AUTOSAR XML (schema 4-0-3)
package /Components
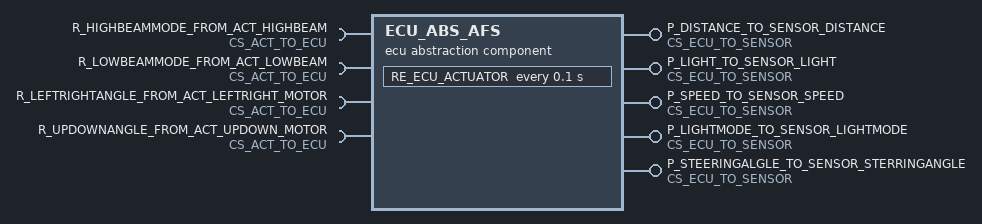
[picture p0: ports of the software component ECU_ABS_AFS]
  ecu abstraction sw component type ECU_ABS_AFS
    4 x require port, all with required-interface=CS_ACT_TO_ECU:
      R_HIGHBEAMMODE_FROM_ACT_HIGHBEAM
      R_LOWBEAMMODE_FROM_ACT_LOWBEAM
      R_LEFTRIGHTANGLE_FROM_ACT_LEFTRIGHT_MOTOR
      R_UPDOWNANGLE_FROM_ACT_UPDOWN_MOTOR
    5 x provide port, all with server-com-spec{operation=OPER_ECU_TO_SENSOR, queue-length=10}, provided-interface=CS_ECU_TO_SENSOR:
      P_DISTANCE_TO_SENSOR_DISTANCE
      P_LIGHT_TO_SENSOR_LIGHT
      P_SPEED_TO_SENSOR_SPEED
      P_LIGHTMODE_TO_SENSOR_LIGHTMODE
      P_STEERINGALGLE_TO_SENSOR_STERRINGANGLE
    behavior IB_ECU_ABS
      timing event TE_ACTUATOR: start-on-event=RE_ECU_ACTUATOR, period=0.1
      5 x operation invoked event:
        OIE_LIGHT: start-on-event=RE_ECU_LIGHT, operation=P_LIGHT_TO_SENSOR_LIGHT.OPER_ECU_TO_SENSOR
        OIE_SPEED: start-on-event=RE_ECU_SPEED, operation=P_SPEED_TO_SENSOR_SPEED.OPER_ECU_TO_SENSOR
        OIE_STEERINGANGLE: start-on-event=RE_ECU_STEERINGANGLE, operation=P_STEERINGALGLE_TO_SENSOR_STERRINGANGLE.OPER_ECU_TO_SENSOR
        OIE_DISTANCE: start-on-event=RE_ECU_DISTANCE, operation=P_DISTANCE_TO_SENSOR_DISTANCE.OPER_ECU_TO_SENSOR
        OIE_LIGHTMODE: start-on-event=RE_ECU_LIGHTMODE, operation=P_LIGHTMODE_TO_SENSOR_LIGHTMODE.OPER_ECU_TO_SENSOR
      6 x runnable:
        RE_ECU_ACTUATOR
          4 x sync call:
            SynchronousServerCallPoint_0: operation=R_UPDOWNANGLE_FROM_ACT_UPDOWN_MOTOR.OPER_ACT_TO_ECU
            SynchronousServerCallPoint_1: operation=R_HIGHBEAMMODE_FROM_ACT_HIGHBEAM.OPER_ACT_TO_ECU
            SynchronousServerCallPoint_2: operation=R_LEFTRIGHTANGLE_FROM_ACT_LEFTRIGHT_MOTOR.OPER_ACT_TO_ECU
            SynchronousServerCallPoint_3: operation=R_LOWBEAMMODE_FROM_ACT_LOWBEAM.OPER_ACT_TO_ECU
        RE_ECU_DISTANCE
        RE_ECU_LIGHT
        RE_ECU_LIGHTMODE
        RE_ECU_SPEED
        RE_ECU_STEERINGANGLE
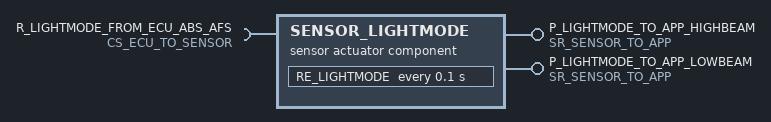
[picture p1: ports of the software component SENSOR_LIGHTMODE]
  sensor actuator sw component type SENSOR_LIGHTMODE
    provide port P_LIGHTMODE_TO_APP_HIGHBEAM: provided-interface=SR_SENSOR_TO_APP
    provide port P_LIGHTMODE_TO_APP_LOWBEAM: provided-interface=SR_SENSOR_TO_APP
    require port R_LIGHTMODE_FROM_ECU_ABS_AFS: required-interface=CS_ECU_TO_SENSOR
    behavior IB_SENSOR_LIGHTMODE
      timing event TE_LIGHTMODE: start-on-event=RE_LIGHTMODE, period=0.1
      runnable RE_LIGHTMODE
        asynchronous server call result point AsynchronousServerCallResultPoint_0: asynchronous-server-call-point=RE_LIGHTMODE/AsynchronousServerCallPoint_0
        data-send-points:
          access DSP_VDP_SENSOR_TO_APP_0: accessed-variable=P_LIGHTMODE_TO_APP_HIGHBEAM.VDP_SENSOR_TO_APP
          access DSP_VDP_SENSOR_TO_APP_1: accessed-variable=P_LIGHTMODE_TO_APP_LOWBEAM.VDP_SENSOR_TO_APP
        async call AsynchronousServerCallPoint_0: operation=R_LIGHTMODE_FROM_ECU_ABS_AFS.OPER_ECU_TO_SENSOR
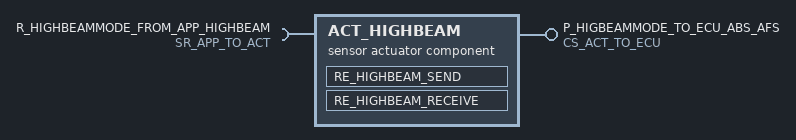
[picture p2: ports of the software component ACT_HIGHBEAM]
  sensor actuator sw component type ACT_HIGHBEAM
    require port R_HIGHBEAMMODE_FROM_APP_HIGHBEAM: required-interface=SR_APP_TO_ACT
    provide port P_HIGBEAMMODE_TO_ECU_ABS_AFS: server-com-spec{operation=OPER_ACT_TO_ECU, queue-length=10}, provided-interface=CS_ACT_TO_ECU
    behavior IB_ACT_HIGHBEAM
      operation invoked event OIE_HIGHBEAM_SEND: start-on-event=RE_HIGHBEAM_SEND, operation=P_HIGBEAMMODE_TO_ECU_ABS_AFS.OPER_ACT_TO_ECU
      data received event DRE_HIGHBEAM_RECEIVE: start-on-event=RE_HIGHBEAM_RECEIVE, data=R_HIGHBEAMMODE_FROM_APP_HIGHBEAM.VDP_APP_TO_ACT
      explicit-inter-runnable-variables:
        data Explicit_VariableDataPrototype_0: type=sint32
      runnable RE_HIGHBEAM_SEND
        read-local-variables:
          access ReadLocalVariables_VariableAccess_0: accessed-variable=IB_ACT_HIGHBEAM/Explicit_VariableDataPrototype_0
      runnable RE_HIGHBEAM_RECEIVE
        data-receive-point-by-values:
          access DRPV_VDP_APP_TO_ACT_0: accessed-variable=R_HIGHBEAMMODE_FROM_APP_HIGHBEAM.VDP_APP_TO_ACT
        written-local-variables:
          access WrittenLocalVariables_VariableAccess_0: accessed-variable=IB_ACT_HIGHBEAM/Explicit_VariableDataPrototype_0
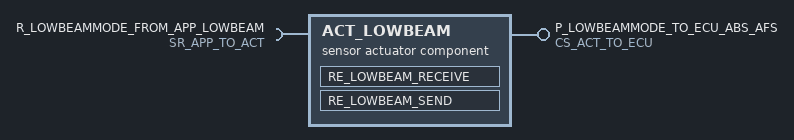
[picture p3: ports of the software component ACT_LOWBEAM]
  sensor actuator sw component type ACT_LOWBEAM
    require port R_LOWBEAMMODE_FROM_APP_LOWBEAM: required-interface=SR_APP_TO_ACT
    provide port P_LOWBEAMMODE_TO_ECU_ABS_AFS: server-com-spec{operation=OPER_ACT_TO_ECU, queue-length=10}, provided-interface=CS_ACT_TO_ECU
    behavior IB_ACT_LOWBEAM
      data received event DRE_LOWBEAM_RECEIVE: start-on-event=RE_LOWBEAM_RECEIVE, data=R_LOWBEAMMODE_FROM_APP_LOWBEAM.VDP_APP_TO_ACT
      operation invoked event OIE_LOWBEAM_SEND: start-on-event=RE_LOWBEAM_SEND, operation=P_LOWBEAMMODE_TO_ECU_ABS_AFS.OPER_ACT_TO_ECU
      explicit-inter-runnable-variables:
        data Explicit_VariableDataPrototype_0: type=sint32
      runnable RE_LOWBEAM_RECEIVE
        data-receive-point-by-values:
          access DRPV_VDP_APP_TO_ACT_0: accessed-variable=R_LOWBEAMMODE_FROM_APP_LOWBEAM.VDP_APP_TO_ACT
        written-local-variables:
          access WrittenLocalVariables_VariableAccess_0: accessed-variable=IB_ACT_LOWBEAM/Explicit_VariableDataPrototype_0
      runnable RE_LOWBEAM_SEND
        read-local-variables:
          access ReadLocalVariables_VariableAccess_0: accessed-variable=IB_ACT_LOWBEAM/Explicit_VariableDataPrototype_0
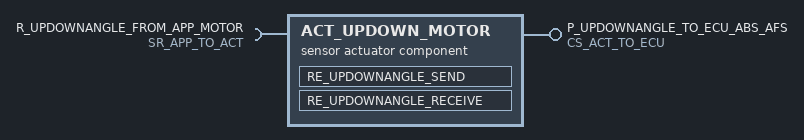
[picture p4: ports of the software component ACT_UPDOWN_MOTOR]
  sensor actuator sw component type ACT_UPDOWN_MOTOR
    require port R_UPDOWNANGLE_FROM_APP_MOTOR: required-interface=SR_APP_TO_ACT
    provide port P_UPDOWNANGLE_TO_ECU_ABS_AFS: server-com-spec{operation=OPER_ACT_TO_ECU, queue-length=10}, provided-interface=CS_ACT_TO_ECU
    behavior IB_ACT_UPDOWN_MOTOR
      operation invoked event OIE_UPDOWNANGLE_SEND: start-on-event=RE_UPDOWNANGLE_SEND, operation=P_UPDOWNANGLE_TO_ECU_ABS_AFS.OPER_ACT_TO_ECU
      data received event DRE_UPDOWNANGLE_RECEIVE: start-on-event=RE_UPDOWNANGLE_RECEIVE, data=R_UPDOWNANGLE_FROM_APP_MOTOR.VDP_APP_TO_ACT
      explicit-inter-runnable-variables:
        data Explicit_VariableDataPrototype_0: type=sint32
      runnable RE_UPDOWNANGLE_SEND
        read-local-variables:
          access ReadLocalVariables_VariableAccess_0: accessed-variable=IB_ACT_UPDOWN_MOTOR/Explicit_VariableDataPrototype_0
      runnable RE_UPDOWNANGLE_RECEIVE
        data-receive-point-by-values:
          access DRPV_VDP_APP_TO_ACT_0: accessed-variable=R_UPDOWNANGLE_FROM_APP_MOTOR.VDP_APP_TO_ACT
        written-local-variables:
          access WrittenLocalVariables_VariableAccess_0: accessed-variable=IB_ACT_UPDOWN_MOTOR/Explicit_VariableDataPrototype_0
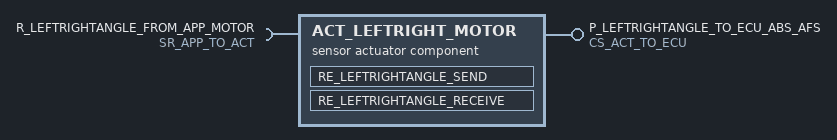
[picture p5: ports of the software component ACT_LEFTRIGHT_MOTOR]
  sensor actuator sw component type ACT_LEFTRIGHT_MOTOR
    require port R_LEFTRIGHTANGLE_FROM_APP_MOTOR: required-interface=SR_APP_TO_ACT
    provide port P_LEFTRIGHTANGLE_TO_ECU_ABS_AFS: server-com-spec{operation=OPER_ACT_TO_ECU, queue-length=10}, provided-interface=CS_ACT_TO_ECU
    behavior IB_ACT_LEFTRIGHT_MOTOR
      data received event DRE_LEFTRIGHTANGLE_RECEIVE: start-on-event=RE_LEFTRIGHTANGLE_RECEIVE, data=R_LEFTRIGHTANGLE_FROM_APP_MOTOR.VDP_APP_TO_ACT
      operation invoked event OIE_LEFTRIGHTANGLE_SEND: start-on-event=RE_LEFTRIGHTANGLE_SEND, operation=P_LEFTRIGHTANGLE_TO_ECU_ABS_AFS.OPER_ACT_TO_ECU
      explicit-inter-runnable-variables:
        data Explicit_VariableDataPrototype_0: type=sint32
      runnable RE_LEFTRIGHTANGLE_SEND
        read-local-variables:
          access ReadLocalVariables_VariableAccess_0: accessed-variable=IB_ACT_LEFTRIGHT_MOTOR/Explicit_VariableDataPrototype_0
      runnable RE_LEFTRIGHTANGLE_RECEIVE
        data-receive-point-by-values:
          access DRPV_VDP_APP_TO_ACT_0: accessed-variable=R_LEFTRIGHTANGLE_FROM_APP_MOTOR.VDP_APP_TO_ACT
        written-local-variables:
          access WrittenLocalVariables_VariableAccess_0: accessed-variable=IB_ACT_LEFTRIGHT_MOTOR/Explicit_VariableDataPrototype_0
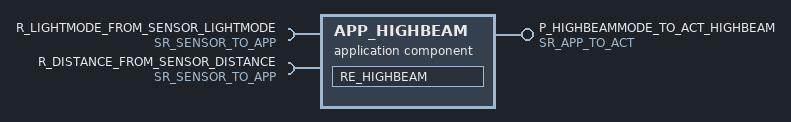
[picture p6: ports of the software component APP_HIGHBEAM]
  application sw component type APP_HIGHBEAM
    require port R_LIGHTMODE_FROM_SENSOR_LIGHTMODE: required-interface=SR_SENSOR_TO_APP
    require port R_DISTANCE_FROM_SENSOR_DISTANCE: required-interface=SR_SENSOR_TO_APP
    provide port P_HIGHBEAMMODE_TO_ACT_HIGHBEAM: provided-interface=SR_APP_TO_ACT
    behavior IB_APP_HIGHBEAM
      data received event DRE_LIGHTMODE: start-on-event=RE_HIGHBEAM, data=R_LIGHTMODE_FROM_SENSOR_LIGHTMODE.VDP_SENSOR_TO_APP
      data received event DRE_DISTANCE: start-on-event=RE_HIGHBEAM, data=R_DISTANCE_FROM_SENSOR_DISTANCE.VDP_SENSOR_TO_APP
      runnable RE_HIGHBEAM
        data-receive-point-by-arguments:
          access DRPA_VDP_SENSOR_TO_APP_0: accessed-variable=R_LIGHTMODE_FROM_SENSOR_LIGHTMODE.VDP_SENSOR_TO_APP
          access DRPA_VDP_SENSOR_TO_APP_1: accessed-variable=R_DISTANCE_FROM_SENSOR_DISTANCE.VDP_SENSOR_TO_APP
        data-send-points:
          access DSP_VDP_APP_TO_ACT_0: accessed-variable=P_HIGHBEAMMODE_TO_ACT_HIGHBEAM.VDP_APP_TO_ACT
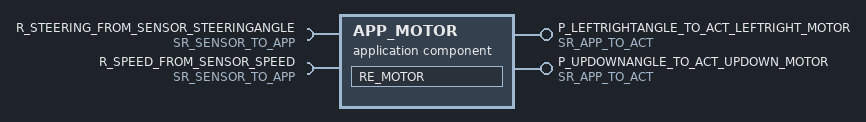
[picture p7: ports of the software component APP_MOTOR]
  application sw component type APP_MOTOR
    require port R_STEERING_FROM_SENSOR_STEERINGANGLE: required-interface=SR_SENSOR_TO_APP
    provide port P_LEFTRIGHTANGLE_TO_ACT_LEFTRIGHT_MOTOR: provided-interface=SR_APP_TO_ACT
    provide port P_UPDOWNANGLE_TO_ACT_UPDOWN_MOTOR: provided-interface=SR_APP_TO_ACT
    require port R_SPEED_FROM_SENSOR_SPEED: required-interface=SR_SENSOR_TO_APP
    behavior IB_APP_MOTOR
      data received event DRE_STEERING: start-on-event=RE_MOTOR, data=R_STEERING_FROM_SENSOR_STEERINGANGLE.VDP_SENSOR_TO_APP
      data received event DRE_SPEED: start-on-event=RE_MOTOR, data=R_SPEED_FROM_SENSOR_SPEED.VDP_SENSOR_TO_APP
      runnable RE_MOTOR
        data-receive-point-by-values:
          access DRPV_VDP_SENSOR_TO_APP_0: accessed-variable=R_STEERING_FROM_SENSOR_STEERINGANGLE.VDP_SENSOR_TO_APP
          access DRPV_VDP_SENSOR_TO_APP_1: accessed-variable=R_SPEED_FROM_SENSOR_SPEED.VDP_SENSOR_TO_APP
        data-send-points:
          access DSP_VDP_APP_TO_ACT_0: accessed-variable=P_LEFTRIGHTANGLE_TO_ACT_LEFTRIGHT_MOTOR.VDP_APP_TO_ACT
          access DSP_VDP_APP_TO_ACT_1: accessed-variable=P_UPDOWNANGLE_TO_ACT_UPDOWN_MOTOR.VDP_APP_TO_ACT
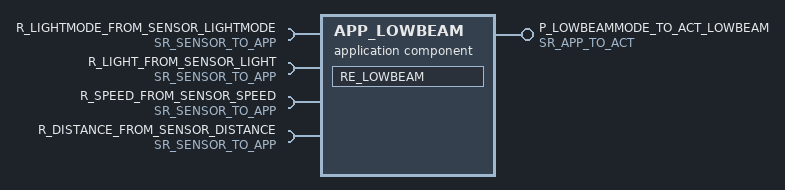
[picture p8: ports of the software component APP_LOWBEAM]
  application sw component type APP_LOWBEAM
    require port R_LIGHTMODE_FROM_SENSOR_LIGHTMODE: required-interface=SR_SENSOR_TO_APP
    require port R_LIGHT_FROM_SENSOR_LIGHT: required-interface=SR_SENSOR_TO_APP
    require port R_SPEED_FROM_SENSOR_SPEED: required-interface=SR_SENSOR_TO_APP
    provide port P_LOWBEAMMODE_TO_ACT_LOWBEAM: provided-interface=SR_APP_TO_ACT
    require port R_DISTANCE_FROM_SENSOR_DISTANCE: required-interface=SR_SENSOR_TO_APP
    behavior IB_APP_LOWBEAM
      4 x data received event, all with start-on-event=RE_LOWBEAM:
        DRE_SPEED: data=R_SPEED_FROM_SENSOR_SPEED.VDP_SENSOR_TO_APP
        DRE_LIGHT: data=R_LIGHT_FROM_SENSOR_LIGHT.VDP_SENSOR_TO_APP
        DRE_LIGHTMODE: data=R_LIGHTMODE_FROM_SENSOR_LIGHTMODE.VDP_SENSOR_TO_APP
        DRE_DISTANCE: data=R_DISTANCE_FROM_SENSOR_DISTANCE.VDP_SENSOR_TO_APP
      runnable RE_LOWBEAM
        data-receive-point-by-values:
          4 x access:
            DRPV_VDP_SENSOR_TO_APP_0: accessed-variable=R_SPEED_FROM_SENSOR_SPEED.VDP_SENSOR_TO_APP
            DRPV_VDP_SENSOR_TO_APP_1: accessed-variable=R_LIGHT_FROM_SENSOR_LIGHT.VDP_SENSOR_TO_APP
            DRPV_VDP_SENSOR_TO_APP_2: accessed-variable=R_LIGHTMODE_FROM_SENSOR_LIGHTMODE.VDP_SENSOR_TO_APP
            DRPV_VDP_SENSOR_TO_APP_3: accessed-variable=R_DISTANCE_FROM_SENSOR_DISTANCE.VDP_SENSOR_TO_APP
        data-send-points:
          access DSP_VDP_APP_TO_ACT_0: accessed-variable=P_LOWBEAMMODE_TO_ACT_LOWBEAM.VDP_APP_TO_ACT
package /ARPackage_1
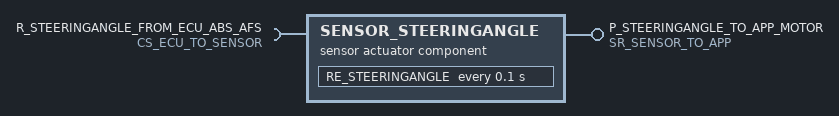
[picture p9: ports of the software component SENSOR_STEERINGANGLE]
  sensor actuator sw component type SENSOR_STEERINGANGLE
    provide port P_STEERINGANGLE_TO_APP_MOTOR: provided-interface=SR_SENSOR_TO_APP
    require port R_STEERINGANGLE_FROM_ECU_ABS_AFS: required-interface=CS_ECU_TO_SENSOR
    behavior IB_SENSOR_STEERINGANGLE
      timing event TE_STEERINGANGLE: start-on-event=RE_STEERINGANGLE, period=0.1
      runnable RE_STEERINGANGLE
        asynchronous server call result point AsynchronousServerCallResultPoint_0: asynchronous-server-call-point=RE_STEERINGANGLE/AsynchronousServerCallPoint_0
        data-send-points:
          access DSP_VDP_SENSOR_TO_APP_0: accessed-variable=P_STEERINGANGLE_TO_APP_MOTOR.VDP_SENSOR_TO_APP
        async call AsynchronousServerCallPoint_0: operation=R_STEERINGANGLE_FROM_ECU_ABS_AFS.OPER_ECU_TO_SENSOR
package /ARPackage_2
  sensor actuator sw component type SENSOR_SPEED
    provide port P_SPEED_TO_APP_LOWBEAM: provided-interface=SR_SENSOR_TO_APP
    require port R_SPEED_FROM_ECU_ABS_AFS: required-interface=CS_ECU_TO_SENSOR
    provide port P_SPEED_TO_APP_MOTOR: provided-interface=SR_SENSOR_TO_APP
    behavior IB_SENSOR_SPEED
      timing event TE_SPEED: start-on-event=RE_SPEED, period=0.1
      runnable RE_SPEED
        asynchronous server call result point AsynchronousServerCallResultPoint_0: asynchronous-server-call-point=RE_SPEED/AsynchronousServerCallPoint_0
        data-send-points:
          access DSP_VDP_SENSOR_TO_APP_0: accessed-variable=P_SPEED_TO_APP_LOWBEAM.VDP_SENSOR_TO_APP
          access DSP_VDP_SENSOR_TO_APP_1: accessed-variable=P_SPEED_TO_APP_MOTOR.VDP_SENSOR_TO_APP
        async call AsynchronousServerCallPoint_0: operation=R_SPEED_FROM_ECU_ABS_AFS.OPER_ECU_TO_SENSOR
package /ARPackage_3
  sensor actuator sw component type SENSOR_DISTANCE
    provide port P_DISTANCE_TO_APP_HIGHBEAM: provided-interface=SR_SENSOR_TO_APP
    require port R_DISTANCE_FROM_ECU_ABS_AFS: required-interface=CS_ECU_TO_SENSOR
    provide port P_DISTANCE_TO_APP_LOWBEAM: provided-interface=SR_SENSOR_TO_APP
    behavior IB_SONSOR_DISTANCE
      timing event TE_DISTANCE: start-on-event=RE_DISTANCE, period=0.1
      runnable RE_DISTANCE
        asynchronous server call result point AsynchronousServerCallResultPoint_0: asynchronous-server-call-point=RE_DISTANCE/AsynchronousServerCallPoint_0
        data-send-points:
          access DSP_VDP_SENSOR_TO_APP_0: accessed-variable=P_DISTANCE_TO_APP_HIGHBEAM.VDP_SENSOR_TO_APP
          access DSP_VDP_SENSOR_TO_APP_1: accessed-variable=P_DISTANCE_TO_APP_LOWBEAM.VDP_SENSOR_TO_APP
        async call AsynchronousServerCallPoint_0: operation=R_DISTANCE_FROM_ECU_ABS_AFS.OPER_ECU_TO_SENSOR
